BO_ 1280 SP_HUD_STATUS: 8 ADAS
 SG_ PROTOCOL_VERSION : 7|4@0+ (1,0) [0|15] "" STM
 SG_ OP_ENABLED : 3|1@0+ (1,0) [0|1] "" STM
 SG_ LAT_ACTIVE : 2|1@0+ (1,0) [0|1] "" STM
 SG_ LONG_ACTIVE : 1|1@0+ (1,0) [0|1] "" STM
 SG_ STEERING_REQUIRED : 0|1@0+ (1,0) [0|1] "" STM
 SG_ LDW_LEFT : 15|1@0+ (1,0) [0|1] "" STM
 SG_ LDW_RIGHT : 14|1@0+ (1,0) [0|1] "" STM
 SG_ FCW : 13|1@0+ (1,0) [0|1] "" STM
 SG_ SOLID_LANES : 12|1@0+ (1,0) [0|1] "" STM
 SG_ DASHED_LANES : 11|1@0+ (1,0) [0|1] "" STM
 SG_ LEAD_VISIBLE : 10|1@0+ (1,0) [0|1] "" STM
 SG_ ALERT_LEVEL : 9|2@0+ (1,0) [0|3] "" STM
 SG_ SET_SPEED : 23|8@0+ (1,0) [0|255] "km/h" STM
 SG_ INTEGRATOR : 31|8@0- (1,0) [-127|127] "" STM
 SG_ INTEGRATOR_FROZEN : 33|1@0+ (1,0) [0|1] "" STM
 SG_ OP_SATURATED : 32|1@0+ (1,0) [0|1] "" STM
 SG_ WANT_CONTROL : 40|1@0+ (1,0) [0|1] "" STM
 SG_ LAT_READY : 41|1@0+ (1,0) [0|1] "" STM
 SG_ OP_STATE : 44|3@0+ (1,0) [0|7] "" STM
 SG_ RELEASE_BRAKE : 45|1@0+ (1,0) [0|1] "" STM
 SG_ RELEASE_DRIVER : 46|1@0+ (1,0) [0|1] "" STM
 SG_ LDW_ACTIVE : 47|1@0+ (1,0) [0|1] "" STM
 SG_ MAX_TORQUE : 55|8@0+ (1,0) [0|255] "counts" STM
 SG_ COUNTER : 61|2@0+ (1,0) [0|3] "" STM
 SG_ CHECKSUM : 59|4@0+ (1,0) [0|15] "" STM

CM_ BO_ 1280 "sunnypilot -> aftermarket HUD module. NOT a stock Honda message: 0x500 was
chosen because it is unused on every bus of this car (81 distinct addresses observed across
buses 0/1/2 over a 26 min route; the whole 0x500-0x5FF range is empty). Nothing in the car
reads it -- it exists so an in-line module at the LKAS camera can merge openpilot's alert
state into the stock LKAS_HUD it is already passing through, WITHOUT openpilot having to
take over 0x33D. Taking over 0x33D would drop the camera's RDM_HUD lane-departure popup and
blind carstate's LKAS_PROBLEM check, which on HONDA_ELESYS reads 0x33D off bus 0.

CHECKSUM and COUNTER are the stock Honda 4-bit / 2-bit pair and are named exactly that so
opendbc's packer fills them automatically -- see get_checksum_state() in opendbc/can/dbc.py,
which keys off the honda_ DBC name prefix. A receiver validates them the same way it would
any Honda frame.

Sent on bus 0, the camera's bus, where the module sits. NOT bus 2: on this harness bus 2 is
the Elesys radar branch, and nothing on it is the module.

PROTOCOL_VERSION is 3. v2 added INTEGRATOR, OP_SATURATED and INTEGRATOR_FROZEN in bytes 3-4;
v3 fills bytes 5-6 with the control request of SP-PROTOCOL-V3 section 1.2. Bytes 0-4 and 7 are
byte-identical to v2, so v3 is a strict superset and the board accepts 1, 2 and 3.

THE VERSION IS A HARD GATE ON THE RECEIVER. The board REJECTS a frame whose version is above
the one it knows (sp_hud.c sp_hud_rx, SP_HUD_VERSION_MAX), and rejecting 0x500 silently takes
the HUD merge and the board's integrator guard down with it. Board firmware 75aa91ee is the
first that accepts 3. Never raise this number ahead of the flashed image.";

CM_ SG_ 1280 STEERING_REQUIRED "openpilot wants hands on the wheel. This is openpilot's own
driver-monitoring nag, NOT the stock camera's -- merge it into LKAS_HUD's STEERING_REQUIRED
by OR, never by overwrite, or a genuine stock warning can be masked.";
CM_ SG_ 1280 ALERT_LEVEL "0 none, 1 info, 2 warning, 3 critical. Severity hint for choosing a
chime; the specific alert is in the flag bits.";
CM_ SG_ 1280 SET_SPEED "0 when no set speed is available. 255 means 255 or above.";
CM_ SG_ 1280 LDW_LEFT "Lane departure to the left. Distinct from the stock camera's RDM_HUD,
which stays on 0x33D and is untouched by openpilot.";

VAL_ 1280 ALERT_LEVEL 3 "critical" 2 "warning" 1 "info" 0 "none" ;

CM_ SG_ 1280 WANT_CONTROL "openpilot intends to steer and is asking. The redundant statement of
the 0x0E4 STEER_TORQUE_REQUEST bit, which remains the thing that actually asks.";
CM_ SG_ 1280 LAT_READY "OPENPILOT'S LATERAL IS ENABLED -- MADS on, including while it is
paused. NOT \"could steer if asked\": it was that once, computed from
`cruiseState.available and vEgo > minSteerSpeed`, which is true with MADS off, and the
board drew dashed lanes whenever the car was moving.

It is mads.enabled, i.e. state in (paused, enabled, softDisabling, overriding), ORed with
latActive for anyone driving without MADS. The paused member is the load-bearing one: the
board pauses openpilot's lateral itself on driver torque, and this staying true through
that is what keeps the cluster's dashed lanes up across an override instead of blanking.

The board reads this in exactly one place - whether to show the lane graphic at all.";
CM_ SG_ 1280 OP_STATE "openpilot's own lateral state machine, NOT the board's. See
GW_STEER_GRANT.STATE for the board's.";
CM_ SG_ 1280 RELEASE_DRIVER "ADVISORY ONLY. openpilot sets it on steeringPressed and
deliberately keeps steering: unlike RELEASE_BRAKE there is no matching ramp on the command,
because the driver-torque blend and the override gate are the board's (INH_DRIVER_OVERRIDE).
Firmware 875ba124 stores the bit and never reads it. If the board ever starts acting on it,
openpilot must ramp here in the same change, or the two sides will disagree about who is
backing off.";
CM_ SG_ 1280 LDW_ACTIVE "A lane-departure warning is being shown on either side. NOT decoded
into anything by firmware 875ba124: sp_hud.c:88 parses it and sp_hud_merge_lkas() never reads
it, so no RDM_HUD or BEEP is raised from it. Sent ahead of the firmware on purpose.";
CM_ SG_ 1280 MAX_TORQUE "The ceiling openpilot is willing to use, in SERIAL counts. 0 means
'use the board's own authority', which is what openpilot sends while the authority ladder is
still moving -- sending the number here as well would mean two places to change it.

NOT ENFORCED BY FIRMWARE 875ba124. The board reads this field in exactly one place,
gw_active.c:1348, and only to compute the AUTHORITY byte it REPORTS on GW_STEER_GRANT. The
command path is unconditional -- gw_active.c:1104,1108 clamp to the compile-time
GW_LIN_AUTHORITY -- so setting a non-zero value here today would make 0x70B AUTHORITY report
the cap while the board kept commanding its own. Harmless while openpilot sends 0, which is
why it does. Do not use this as a probe-drive limiter until the board applies the negotiated
value at gw_active.c:1104,1108.";

VAL_ 1280 OP_STATE 5 "faulted" 4 "withdrawing" 3 "active" 2 "requesting" 1 "ready" 0 "off" ;

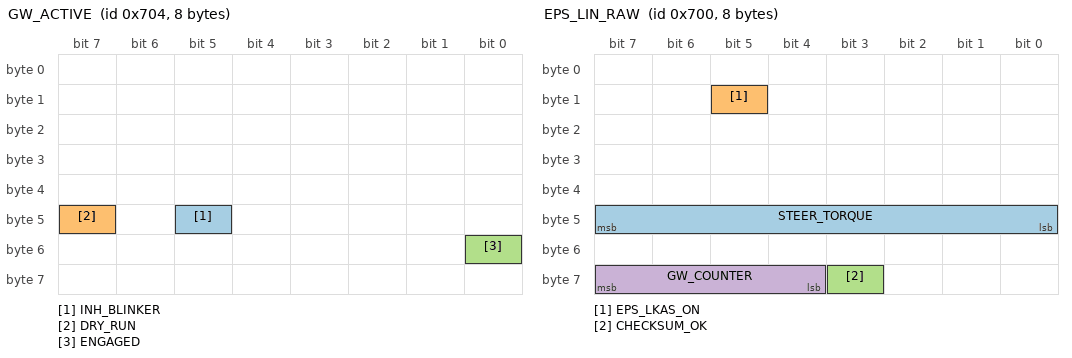
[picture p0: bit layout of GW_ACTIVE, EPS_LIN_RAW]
BO_ 1796 GW_ACTIVE: 8 STM
 SG_ INH_BLINKER : 45|1@0+ (1,0) [0|1] "" ADAS
 SG_ DRY_RUN : 47|1@0+ (1,0) [0|1] "" ADAS
 SG_ ENGAGED : 48|1@0+ (1,0) [0|1] "" ADAS

CM_ BO_ 1796 "LIN-bus gateway -> sunnypilot. The board's own status, at 10 Hz on the car bus.
NOT a stock Honda message. Only the three bits sunnypilot reads are defined here; the board's
own DBC (eps-lkas-gw.dbc) carries the rest, and this file deliberately does not duplicate them
so there is one place to change when the board's layout moves.

There is no CHECKSUM or COUNTER signal on purpose. The board does not compute a Honda checksum
for this frame, and naming a signal CHECKSUM in a honda_ DBC would make opendbc's parser try to
validate one -- see get_checksum_state() in opendbc/can/dbc.py.";

CM_ SG_ 1796 ENGAGED "The board is commanding non-zero torque on the LIN line.";
CM_ SG_ 1796 DRY_RUN "The board is NOT actuating anything -- it reports what it WOULD do.
ENGAGED is still set in a dry run, so ENGAGED alone means 'the board has an opinion', not
'the loop is closed'. Every consumer must read ENGAGED AND NOT DRY_RUN.";
CM_ SG_ 1796 INH_BLINKER "A turn signal is on, or went off less than 500 ms ago
(GW_BLINKER_DWELL_MS). Since the board's Stage 8 this is a CEILING, not a stop: while it is set
the board keeps commanding but clamps to GW_BLINK_CEIL_PCT (50 at board 686e4603) percent of
its authority (gw_active.c, the S8-1 ceiling). Decoded into carStateSP.linbusGateway.blinkerCapped
and logged; openpilot does not act on it. The reported torque is deliberately not clipped to the
ceiling, which would stop the steerSaturated alert while the blinker is on (carcontroller.py).";

BO_ 1792 EPS_LIN_RAW: 8 STM
 SG_ STEER_TORQUE : 40|8@1- (2,0) [-256|254] "counts" ADAS
 SG_ EPS_LKAS_ON : 13|1@1+ (1,0) [0|1] "" ADAS
 SG_ CHECKSUM_OK : 59|1@1+ (1,0) [0|1] "" ADAS
 SG_ GW_COUNTER : 60|4@1+ (1,0) [0|15] "" ADAS

CM_ BO_ 1792 "LIN-bus gateway -> sunnypilot. The board's mirror of the EPS's own serial frame,
one CAN frame per serial frame, so 100 Hz. NOT a stock Honda message.

This is the ONLY live driver-torque signal on this car while openpilot is steering. The EPS
stops updating STEER_TORQUE_SENSOR on 0x18F for as long as it is under LKAS control -- the
frame keeps arriving at 100 Hz with a rolling counter and a valid checksum, and the torque
byte simply holds the value it had when LKAS engaged. That is the EPS's own behaviour, not
the board's: it is visible on route 0000001f, recorded before this board existed, where a
7.7 s stock LKAS engagement contains a 4.7 s frozen run. With the board fitted the
engagements are long, so the frozen fraction goes from 36 % to 99 %.

Only the four signals sunnypilot acts on are declared here. The board's own DBC
(dbc/eps-lkas-gw.dbc in the gateway firmware repo) carries the rest of the frame, including
the raw nibbles this STEER_TORQUE is assembled from, and this file deliberately does not
duplicate them.

Little-endian, matching the board's DBC. Note the two names that must NOT change: a signal
called CHECKSUM or COUNTER in a honda_ DBC makes opendbc's parser try to validate a Honda
checksum and enforce counter continuity -- see get_checksum_state() in opendbc/can/dbc.py --
and the board computes neither for this frame.";

CM_ SG_ 1792 STEER_TORQUE "Driver torque in EPS serial counts, scale 2, LEFT NEGATIVE --
the opposite sign to CarState.steeringTorque. carstate_ext converts:
steeringTorque = -64.5 * STEER_TORQUE. That constant is a least-squares fit against 0x18F
over the 30 482 samples of routes dd/de/df where both were live, R^2 0.9991, residual RMS
134 CAN counts. Converting rather than rescaling the thresholds is deliberate: every
consumer of steeringTorque, and every STEER_THRESHOLD, keeps working unchanged, and the
logs stay comparable with the drives from before the board was fitted.";
CM_ SG_ 1792 CHECKSUM_OK "The board's verdict on the EPS serial frame's own checksum. 1.000
across every frame of routes dd/de/df. Do not substitute this torque for the car's when it
is 0.";

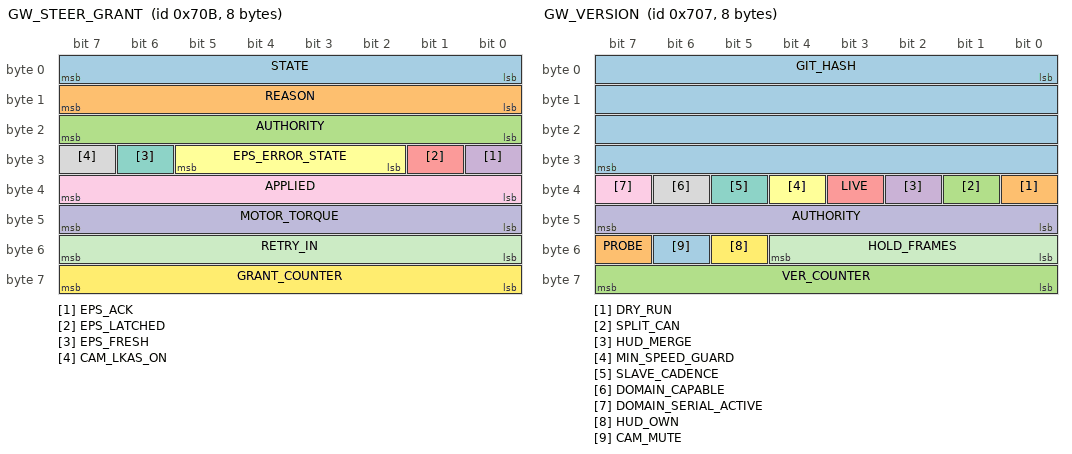
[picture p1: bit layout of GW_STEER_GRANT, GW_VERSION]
BO_ 1803 GW_STEER_GRANT: 8 STM
 SG_ STATE : 7|8@0+ (1,0) [0|7] "" ADAS
 SG_ REASON : 15|8@0+ (1,0) [0|15] "" ADAS
 SG_ AUTHORITY : 23|8@0+ (1,0) [0|255] "counts" ADAS
 SG_ EPS_ACK : 24|1@0+ (1,0) [0|1] "" ADAS
 SG_ EPS_LATCHED : 25|1@0+ (1,0) [0|1] "" ADAS
 SG_ EPS_ERROR_STATE : 29|4@0+ (1,0) [0|15] "" ADAS
 SG_ EPS_FRESH : 30|1@0+ (1,0) [0|1] "" ADAS
 SG_ CAM_LKAS_ON : 31|1@0+ (1,0) [0|1] "" ADAS
 SG_ APPLIED : 39|8@0- (2,0) [-256|254] "counts" ADAS
 SG_ MOTOR_TORQUE : 47|8@0- (4,0) [-512|508] "" ADAS
 SG_ RETRY_IN : 55|8@0+ (1,0) [0|255] "s" ADAS
 SG_ GRANT_COUNTER : 63|8@0+ (1,0) [0|255] "" ADAS

CM_ BO_ 1803 "LIN-bus gateway -> sunnypilot, 10 Hz on the car bus. NOT a stock Honda message.
New in SP-PROTOCOL v3; board firmware 75aa91ee is the first that sends it, so IT MAY BE ABSENT
and absence must read as NOT GRANTED. It is registered liveness-exempt in carstate's
get_can_parsers() for exactly that reason -- see the note on GW_ACTIVE below.

Why it exists: 0x704 GW_ACTIVE says whether the board is actuating, and has no room left to
say WHY it is not. This frame carries the reason, in openpilot's own terms, so the driver can
be told something better than 'it is not steering'.

The counter is GRANT_COUNTER, NOT COUNTER, and there is no CHECKSUM signal. Both names are
load-bearing in a honda_ DBC: opendbc's parser keys off them (get_checksum_state() /
set_signal_type() in opendbc/can/dbc.py) and would enforce Honda counter continuity and a
Honda checksum on a frame the board computes neither for -- dropping every frame.

Bit layout is transcribed from the board's own dbc/eps-lkas-gw.dbc, which is written
little-endian; the start bits here are the big-endian (Motorola) spelling of the same physical
bits, matching the rest of this file.";

CM_ SG_ 1803 STATE "The board's steering state machine. Only INTRO, ACTIVE and LIMITED mean it
is or is about to be putting torque on the serial line.";
CM_ SG_ 1803 REASON "Why the board is not steering. 0 while it is. Value 6 'brake' is defined
in the protocol but NOT emitted by firmware 875ba124: GW_RSN_BRAKE exists at gw_active.c:234
and the reason ladder at gw_active.c:1356-1375 has no brake branch, so a brake-time withdrawal
arrives as 1 'no_request'.";
CM_ SG_ 1803 AUTHORITY "The board's current ceiling in SERIAL counts, as the board REPORTS it.
Informational: openpilot stays in the 2560 CAN domain and the board scales by AUTHORITY/2560,
so openpilot's full scale IS this number whatever it is. Note that firmware 875ba124 folds
SP_HUD_STATUS.MAX_TORQUE into this byte only -- it does not apply it to the command. See the
MAX_TORQUE comment above.";
CM_ SG_ 1803 EPS_LATCHED "NOT a key-cycle latch, despite the name. It is the board's `refusing`
flag (gw_active.c:1391), a TIMED hold: GW_REFUSE_HOLD_MS = 60 s when the EPS reports an error
state, GW_NOACK_HOLD_MS = 3 s when it merely fails to acknowledge (gw_active.c:1017-1022).
Read it as 'the board is inside its refusal hold'. RETRY_IN is what separates the two.";
CM_ SG_ 1803 EPS_ERROR_STATE "Serial B2 bits 2:0 with B0 bit 4 as its top bit. 4 is the code
this EPS returns when it refuses a torque request, and it latches for the key cycle.";
CM_ SG_ 1803 RETRY_IN "Seconds until a new request will be considered. 0 = now. 255 = NOT THIS
KEY CYCLE: the EPS has latched and only an ignition cycle clears it, so say so to the driver
rather than retrying into a dead EPS for the rest of the drive. THE ONLY KEY-CYCLE STATEMENT
THE BOARD MAKES -- it emits 255 only while refusing with a non-zero EPS error state
(gw_active.c:1401-1406); for a plain no-acknowledgement it counts a finite hold down instead.";
CM_ SG_ 1803 APPLIED "Serial counts actually put on the wire, scale 2 -- and therefore
QUANTISED to 2 counts: the board packs (int8)(cmd / 2) with C truncation toward zero
(gw_active.c:1394), so a commanded +/-1 reads back as 0. Use STATE, or 0x704 CMD_APPLY_STEER,
for any 'is anything on the wire' check.";

VAL_ 1803 STATE 7 "board_fault" 6 "refused" 5 "limited" 4 "active" 3 "intro" 2 "requested" 1 "ready" 0 "idle" ;
VAL_ 1803 REASON 15 "soft_start" 14 "dry_run" 13 "board_fault" 12 "camera_fault" 11 "integrator_too_large" 10 "serial_checksum" 9 "eps_no_ack" 8 "eps_refused_latched" 7 "standstill" 6 "brake" 5 "blinker" 4 "driver_override" 3 "speed_too_low" 2 "op_stale" 1 "no_request" 0 "none" ;

BO_ 1799 GW_VERSION: 8 STM
 SG_ GIT_HASH : 0|32@1+ (1,0) [0|4294967295] "" ADAS
 SG_ DRY_RUN : 32|1@1+ (1,0) [0|1] "" ADAS
 SG_ SPLIT_CAN : 33|1@1+ (1,0) [0|1] "" ADAS
 SG_ HUD_MERGE : 34|1@1+ (1,0) [0|1] "" ADAS
 SG_ LIVE : 35|1@1+ (1,0) [0|1] "" ADAS
 SG_ MIN_SPEED_GUARD : 36|1@1+ (1,0) [0|1] "" ADAS
 SG_ SLAVE_CADENCE : 37|1@1+ (1,0) [0|1] "" ADAS
 SG_ DOMAIN_CAPABLE : 38|1@1+ (1,0) [0|1] "" ADAS
 SG_ DOMAIN_SERIAL_ACTIVE : 39|1@1+ (1,0) [0|1] "" ADAS
 SG_ AUTHORITY : 40|8@1+ (1,0) [0|255] "counts" ADAS
 SG_ HOLD_FRAMES : 48|5@1+ (1,0) [0|31] "" ADAS
 SG_ HUD_OWN : 53|1@1+ (1,0) [0|1] "" ADAS
 SG_ CAM_MUTE : 54|1@1+ (1,0) [0|1] "" ADAS
 SG_ PROBE : 55|1@1+ (1,0) [0|1] "" ADAS
 SG_ VER_COUNTER : 56|8@1+ (1,0) [0|255] "" ADAS

CM_ BO_ 1799 "LIN-bus gateway -> sunnypilot. WHICH FIRMWARE IS ON THE BOARD, and the only
answer any log or any screen gets. Sent once at mode entry and once a minute -- NOT 10 Hz --
from gw_active.c:1267 and :2519. Little-endian, unlike the 0x70B block above: the board packs
these bytes LSB-first, so the 32-bit hash is @1+ and not @0+.

NOT SENT AT ALL by the INCAR_READONLY stand-down image before firmware 52ca4732, and never
sent by a board sitting in its CAN bootloader -- that one answers on 0x711 instead. So an
absent GW_VERSION means 'nothing told us', never 'no board'.";
CM_ SG_ 1799 GIT_HASH "The first 8 hex digits of the commit the image was BUILT FROM, baked in
by CMake at configure time. Read it as %08x and it greps against the firmware repo's git log
and against docs/CAN-UPDATE.md directly.

IT CAN LIE, and 0x70F BUILD_DIRTY is how you find out: before firmware 52ca4732 there was no
dirty-tree check, so an image built from an edited working tree reported its PARENT commit
here as though it were that commit.";
CM_ SG_ 1799 AUTHORITY "The compile-time GW_LIN_AUTHORITY, not the negotiated ceiling. 0x70B
AUTHORITY carries the one actually in force, which sunnypilot's 0x500 can pull down, so the
two legitimately disagree.";
CM_ SG_ 1799 HOLD_FRAMES "Compile-time GW_MAX_HOLD_FRAMES, 25 on every Stage 3/4 image and 0
on Stage 2a. It distinguishes nothing between current builds; it is here because it was here.";

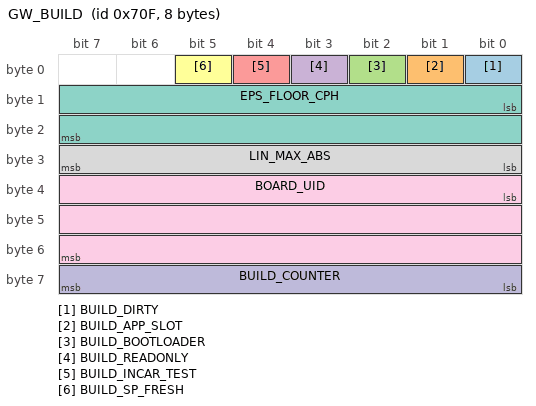
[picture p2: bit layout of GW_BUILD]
BO_ 1807 GW_BUILD: 8 STM
 SG_ BUILD_DIRTY : 0|1@1+ (1,0) [0|1] "" ADAS
 SG_ BUILD_APP_SLOT : 1|1@1+ (1,0) [0|1] "" ADAS
 SG_ BUILD_BOOTLOADER : 2|1@1+ (1,0) [0|1] "" ADAS
 SG_ BUILD_READONLY : 3|1@1+ (1,0) [0|1] "" ADAS
 SG_ BUILD_INCAR_TEST : 4|1@1+ (1,0) [0|1] "" ADAS
 SG_ BUILD_SP_FRESH : 5|1@1+ (1,0) [0|1] "" ADAS
 SG_ EPS_FLOOR_CPH : 8|16@1+ (1,0) [0|65535] "0.01 km/h" ADAS
 SG_ LIN_MAX_ABS : 24|8@1+ (1,0) [0|255] "counts" ADAS
 SG_ BOARD_UID : 32|24@1+ (1,0) [0|16777215] "" ADAS
 SG_ BUILD_COUNTER : 56|8@1+ (1,0) [0|255] "" ADAS

CM_ BO_ 1807 "Board and build identity, sent beside 0x707. Answers what 0x707 structurally
cannot, because its flag byte is full.

NEW IN FIRMWARE 625b782a. A board running anything older sends 0x707 and not this, which is
itself informative: no GW_BUILD means firmware older than 2026-09-22, which in turn means no
CAN bootloader and no on-screen update.";
CM_ SG_ 1807 BUILD_SP_FRESH "0x500 SP_HUD_STATUS is arriving and fresh, sampled at the instant this beat was sent. RUNTIME, not build -- it is on this frame because byte 0 had room. It answers the one question a log could not: the board's lane graphic hangs on a bit carried in 0x500, and with no telemetry for it, \"the HUD is wrong\" and \"the side channel never arrived\" looked identical. Two drives were spent guessing between them.";
CM_ SG_ 1807 BUILD_BOOTLOADER "A bootloader really is present at 0x08000000, checked at RUN
TIME rather than assumed from build flags -- the firmware reads the reset vector there. THIS
IS THE BIT THAT SAYS THE BOARD CAN BE UPDATED OVER CAN AT ALL. Clear means the board has
never had its one-time SWD visit and will ignore the entire update procedure.";
CM_ SG_ 1807 BUILD_APP_SLOT "Linked for 0x08004000 to run under the bootloader, rather than
standalone at 0x08000000. The two are not interchangeable: a standalone image installed in the
app slot passes every structural check and then gets branched into 16 KB from its real reset
handler, which is why images carry a marker recording the address they were linked for.";
CM_ SG_ 1807 BUILD_DIRTY "The image was built from an edited working tree, so GIT_HASH on
0x707 names a commit it was NOT built from. Set by CMake, which also warns at configure time.";
CM_ SG_ 1807 BOARD_UID "The 96-bit MCU unique ID folded to 24 bits -- i.e. WHICH PHYSICAL
BOARD. Before this existed, board_read_device_id() was only ever called from the self-test,
which verify_incar.py forbids in an in-car image, so no route could tell the car's board from
a spare one on the bench.";
CM_ SG_ 1807 EPS_FLOOR_CPH "GW_EPS_ACK_CPH, the speed below which the EPS will not acknowledge
a torque request. With LIN_MAX_ABS this is what separates two otherwise identical images in a
log -- the Stage 10 image and the 30 km/h floor test differ in little else.";
